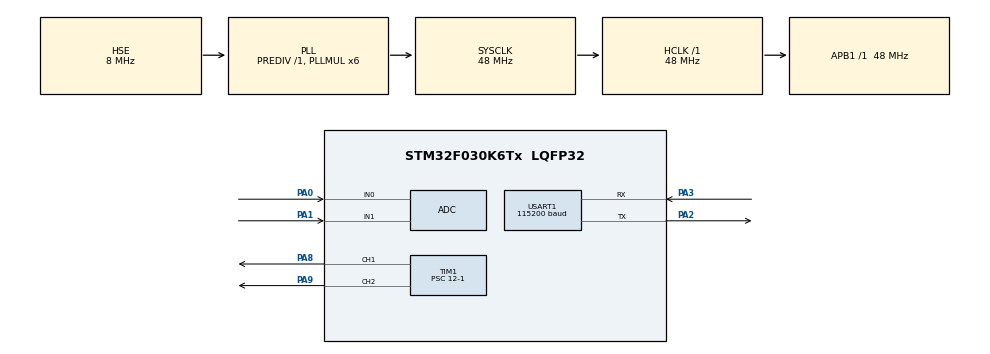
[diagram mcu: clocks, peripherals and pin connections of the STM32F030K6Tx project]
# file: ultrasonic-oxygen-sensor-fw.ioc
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ADC.ClockPrescaler=ADC_CLOCK_SYNC_PCLK_DIV4
ADC.ContinuousConvMode=ENABLE
ADC.DMAContinuousRequests=ENABLE
Dma.ADC.0.Direction=DMA_PERIPH_TO_MEMORY
Dma.ADC.0.Instance=DMA1_Channel1
Dma.ADC.0.MemDataAlignment=DMA_MDATAALIGN_HALFWORD
Dma.ADC.0.MemInc=DMA_MINC_ENABLE
Dma.ADC.0.Mode=DMA_NORMAL
Dma.ADC.0.PeriphDataAlignment=DMA_PDATAALIGN_HALFWORD
Dma.ADC.0.PeriphInc=DMA_PINC_DISABLE
Dma.ADC.0.Priority=DMA_PRIORITY_LOW
Dma.Request0=ADC
Mcu.Family=STM32F0
Mcu.Name=STM32F030K6Tx
Mcu.Package=LQFP32
NVIC.DMA1_Channel1_IRQn=true\:0\:0\:false\:false\:true\:false\:true
NVIC.TIM1_BRK_UP_TRG_COM_IRQn=true\:0\:0\:false\:false\:true\:true\:true
NVIC.TIM1_CC_IRQn=true\:0\:0\:false\:false\:true\:true\:true
PA0.Mode=IN0
PA0.Signal=ADC_IN0
PA1.Mode=IN1
PA1.Signal=ADC_IN1
PA13.Mode=Serial_Wire
PA13.Signal=SYS_SWDIO
PA14.Mode=Serial_Wire
PA14.Signal=SYS_SWCLK
PA2.Mode=Asynchronous
PA2.Signal=USART1_TX
PA3.Mode=Asynchronous
PA3.Signal=USART1_RX
PA8.Signal=S_TIM1_CH1
PA9.Signal=S_TIM1_CH2
PF0-OSC_IN.Mode=HSE-External-Oscillator
PF0-OSC_IN.Signal=RCC_OSC_IN
PF1-OSC_OUT.Mode=HSE-External-Oscillator
PF1-OSC_OUT.Signal=RCC_OSC_OUT
ProjectManager.HeapSize=0x200
ProjectManager.StackSize=0x400
ProjectManager.TargetToolchain=SW4STM32
RCC.AHBFreq_Value=48000000
RCC.APB1Freq_Value=48000000
RCC.APB1TimFreq_Value=48000000
RCC.HCLKFreq_Value=48000000
RCC.PLLMUL=RCC_PLL_MUL6
RCC.PLLSourceVirtual=RCC_PLLSOURCE_HSE
RCC.SYSCLKFreq_VALUE=48000000
RCC.SYSCLKSource=RCC_SYSCLKSOURCE_PLLCLK
SH.S_TIM1_CH1.0=TIM1_CH1,PWM Generation1 CH1
SH.S_TIM1_CH2.0=TIM1_CH2,PWM Generation2 CH2
TIM1.Channel-PWM\ Generation1\ CH1=TIM_CHANNEL_1
TIM1.Channel-PWM\ Generation2\ CH2=TIM_CHANNEL_2
TIM1.CounterMode=TIM_COUNTERMODE_DOWN
TIM1.Period=100-1
TIM1.Prescaler=12-1
USART1.BaudRate=115200
USART1.VirtualMode-Asynchronous=VM_ASYNC
VP_TIM1_VS_ClockSourceINT.Mode=Internal
board=custom

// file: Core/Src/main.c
/* USER CODE BEGIN Header */
/**
  ******************************************************************************
  * @file           : main.c
  * @brief          : Main program body
  ******************************************************************************
  * @attention
  *
  * <h2><center>&copy; Copyright (c) 2020 STMicroelectronics.
  * All rights reserved.</center></h2>
  *
  * This software component is licensed by ST under BSD 3-Clause license,
  * the "License"; You may not use this file except in compliance with the
  * License. You may obtain a copy of the License at:
  *                        opensource.org/licenses/BSD-3-Clause
  *
  ******************************************************************************
  */
/* USER CODE END Header */

#include "main.h"

/* USER CODE BEGIN Includes */
#include "sensor.h"
/* USER CODE END Includes */

ADC_HandleTypeDef hadc;
DMA_HandleTypeDef hdma_adc;

TIM_HandleTypeDef htim1;

UART_HandleTypeDef huart1;

void SystemClock_Config(void);
static void MX_GPIO_Init(void);
static void MX_DMA_Init(void);
static void MX_ADC_Init(void);
static void MX_TIM1_Init(void);
static void MX_USART1_UART_Init(void);

int main(void)
{

  /* MCU Configuration--------------------------------------------------------*/

  /* Reset of all peripherals, Initializes the Flash interface and the Systick. */
  HAL_Init();

  /* Configure the system clock */
  SystemClock_Config();

  /* Initialize all configured peripherals */
  MX_GPIO_Init();
  MX_DMA_Init();
  MX_ADC_Init();
  MX_TIM1_Init();
  MX_USART1_UART_Init();
  /* USER CODE BEGIN 2 */
  //printf("Sensor init....\r\n");
  SENSOR_Init();
  /* USER CODE END 2 */

  /* Infinite loop */
  while (1)
  {

  }
}

void SystemClock_Config(void)
{
  RCC_OscInitTypeDef RCC_OscInitStruct = {0};
  RCC_ClkInitTypeDef RCC_ClkInitStruct = {0};
  RCC_PeriphCLKInitTypeDef PeriphClkInit = {0};

  /** Initializes the CPU, AHB and APB busses clocks
  */
  RCC_OscInitStruct.OscillatorType = RCC_OSCILLATORTYPE_HSE;
  RCC_OscInitStruct.HSEState = RCC_HSE_ON;
  RCC_OscInitStruct.PLL.PLLState = RCC_PLL_ON;
  RCC_OscInitStruct.PLL.PLLSource = RCC_PLLSOURCE_HSE;
  RCC_OscInitStruct.PLL.PLLMUL = RCC_PLL_MUL6;
  RCC_OscInitStruct.PLL.PREDIV = RCC_PREDIV_DIV1;
  if (HAL_RCC_OscConfig(&RCC_OscInitStruct) != HAL_OK)
  {
    Error_Handler();
  }
  /** Initializes the CPU, AHB and APB busses clocks
  */
  RCC_ClkInitStruct.ClockType = RCC_CLOCKTYPE_HCLK|RCC_CLOCKTYPE_SYSCLK
                              |RCC_CLOCKTYPE_PCLK1;
  RCC_ClkInitStruct.SYSCLKSource = RCC_SYSCLKSOURCE_PLLCLK;
  RCC_ClkInitStruct.AHBCLKDivider = RCC_SYSCLK_DIV1;
  RCC_ClkInitStruct.APB1CLKDivider = RCC_HCLK_DIV1;

  if (HAL_RCC_ClockConfig(&RCC_ClkInitStruct, FLASH_LATENCY_1) != HAL_OK)
  {
    Error_Handler();
  }
  PeriphClkInit.PeriphClockSelection = RCC_PERIPHCLK_USART1;
  PeriphClkInit.Usart1ClockSelection = RCC_USART1CLKSOURCE_PCLK1;
  if (HAL_RCCEx_PeriphCLKConfig(&PeriphClkInit) != HAL_OK)
  {
    Error_Handler();
  }
}

static void MX_ADC_Init(void)
{

  ADC_ChannelConfTypeDef sConfig = {0};

  /** Configure the global features of the ADC (Clock, Resolution, Data Alignment and number of conversion)
  */
  hadc.Instance = ADC1;
  hadc.Init.ClockPrescaler = ADC_CLOCK_SYNC_PCLK_DIV4;
  hadc.Init.Resolution = ADC_RESOLUTION_12B;
  hadc.Init.DataAlign = ADC_DATAALIGN_RIGHT;
  hadc.Init.ScanConvMode = ADC_SCAN_DIRECTION_FORWARD;
  hadc.Init.EOCSelection = ADC_EOC_SINGLE_CONV;
  hadc.Init.LowPowerAutoWait = DISABLE;
  hadc.Init.LowPowerAutoPowerOff = DISABLE;
  hadc.Init.ContinuousConvMode = ENABLE;
  hadc.Init.DiscontinuousConvMode = DISABLE;
  hadc.Init.ExternalTrigConv = ADC_SOFTWARE_START;
  hadc.Init.ExternalTrigConvEdge = ADC_EXTERNALTRIGCONVEDGE_NONE;
  hadc.Init.DMAContinuousRequests = ENABLE;
  hadc.Init.Overrun = ADC_OVR_DATA_PRESERVED;
  if (HAL_ADC_Init(&hadc) != HAL_OK)
  {
    Error_Handler();
  }
  /** Configure for the selected ADC regular channel to be converted.
  */
  sConfig.Channel = ADC_CHANNEL_0;
  sConfig.Rank = ADC_RANK_CHANNEL_NUMBER;
  sConfig.SamplingTime = ADC_SAMPLETIME_1CYCLE_5;
  if (HAL_ADC_ConfigChannel(&hadc, &sConfig) != HAL_OK)
  {
    Error_Handler();
  }
  /** Configure for the selected ADC regular channel to be converted.
  */
  sConfig.Channel = ADC_CHANNEL_1;
  if (HAL_ADC_ConfigChannel(&hadc, &sConfig) != HAL_OK)
  {
    Error_Handler();
  }

}

static void MX_TIM1_Init(void)
{

  TIM_ClockConfigTypeDef sClockSourceConfig = {0};
  TIM_MasterConfigTypeDef sMasterConfig = {0};
  TIM_OC_InitTypeDef sConfigOC = {0};
  TIM_BreakDeadTimeConfigTypeDef sBreakDeadTimeConfig = {0};

  htim1.Instance = TIM1;
  htim1.Init.Prescaler = 12-1;
  htim1.Init.CounterMode = TIM_COUNTERMODE_DOWN;
  htim1.Init.Period = 100-1;
  htim1.Init.ClockDivision = TIM_CLOCKDIVISION_DIV1;
  htim1.Init.RepetitionCounter = 0;
  htim1.Init.AutoReloadPreload = TIM_AUTORELOAD_PRELOAD_DISABLE;
  if (HAL_TIM_Base_Init(&htim1) != HAL_OK)
  {
    Error_Handler();
  }
  sClockSourceConfig.ClockSource = TIM_CLOCKSOURCE_INTERNAL;
  if (HAL_TIM_ConfigClockSource(&htim1, &sClockSourceConfig) != HAL_OK)
  {
    Error_Handler();
  }
  if (HAL_TIM_PWM_Init(&htim1) != HAL_OK)
  {
    Error_Handler();
  }
  sMasterConfig.MasterOutputTrigger = TIM_TRGO_RESET;
  sMasterConfig.MasterSlaveMode = TIM_MASTERSLAVEMODE_DISABLE;
  if (HAL_TIMEx_MasterConfigSynchronization(&htim1, &sMasterConfig) != HAL_OK)
  {
    Error_Handler();
  }
  sConfigOC.OCMode = TIM_OCMODE_PWM1;
  sConfigOC.Pulse = 0;
  sConfigOC.OCPolarity = TIM_OCPOLARITY_HIGH;
  sConfigOC.OCNPolarity = TIM_OCNPOLARITY_HIGH;
  sConfigOC.OCFastMode = TIM_OCFAST_DISABLE;
  sConfigOC.OCIdleState = TIM_OCIDLESTATE_RESET;
  sConfigOC.OCNIdleState = TIM_OCNIDLESTATE_RESET;
  if (HAL_TIM_PWM_ConfigChannel(&htim1, &sConfigOC, TIM_CHANNEL_1) != HAL_OK)
  {
    Error_Handler();
  }
  if (HAL_TIM_PWM_ConfigChannel(&htim1, &sConfigOC, TIM_CHANNEL_2) != HAL_OK)
  {
    Error_Handler();
  }
  sBreakDeadTimeConfig.OffStateRunMode = TIM_OSSR_DISABLE;
  sBreakDeadTimeConfig.OffStateIDLEMode = TIM_OSSI_DISABLE;
  sBreakDeadTimeConfig.LockLevel = TIM_LOCKLEVEL_OFF;
  sBreakDeadTimeConfig.DeadTime = 0;
  sBreakDeadTimeConfig.BreakState = TIM_BREAK_DISABLE;
  sBreakDeadTimeConfig.BreakPolarity = TIM_BREAKPOLARITY_HIGH;
  sBreakDeadTimeConfig.AutomaticOutput = TIM_AUTOMATICOUTPUT_DISABLE;
  if (HAL_TIMEx_ConfigBreakDeadTime(&htim1, &sBreakDeadTimeConfig) != HAL_OK)
  {
    Error_Handler();
  }
  HAL_TIM_MspPostInit(&htim1);

}

static void MX_USART1_UART_Init(void)
{

  huart1.Instance = USART1;
  huart1.Init.BaudRate = 115200;
  huart1.Init.WordLength = UART_WORDLENGTH_8B;
  huart1.Init.StopBits = UART_STOPBITS_1;
  huart1.Init.Parity = UART_PARITY_NONE;
  huart1.Init.Mode = UART_MODE_TX_RX;
  huart1.Init.HwFlowCtl = UART_HWCONTROL_NONE;
  huart1.Init.OverSampling = UART_OVERSAMPLING_16;
  huart1.Init.OneBitSampling = UART_ONE_BIT_SAMPLE_DISABLE;
  huart1.AdvancedInit.AdvFeatureInit = UART_ADVFEATURE_NO_INIT;
  if (HAL_UART_Init(&huart1) != HAL_OK)
  {
    Error_Handler();
  }

}

static void MX_DMA_Init(void)
{

  /* DMA controller clock enable */
  __HAL_RCC_DMA1_CLK_ENABLE();

  /* DMA interrupt init */
  /* DMA1_Channel1_IRQn interrupt configuration */
  HAL_NVIC_SetPriority(DMA1_Channel1_IRQn, 0, 0);
  HAL_NVIC_EnableIRQ(DMA1_Channel1_IRQn);

}

static void MX_GPIO_Init(void)
{

  /* GPIO Ports Clock Enable */
  __HAL_RCC_GPIOF_CLK_ENABLE();
  __HAL_RCC_GPIOA_CLK_ENABLE();

}

/* USER CODE BEGIN 4 */
/* Retarget printf to UART (std library and toolchain dependent) */

/* USER CODE END 4 */

void Error_Handler(void)
{
}

/************************ (C) COPYRIGHT STMicroelectronics *****END OF FILE****/
